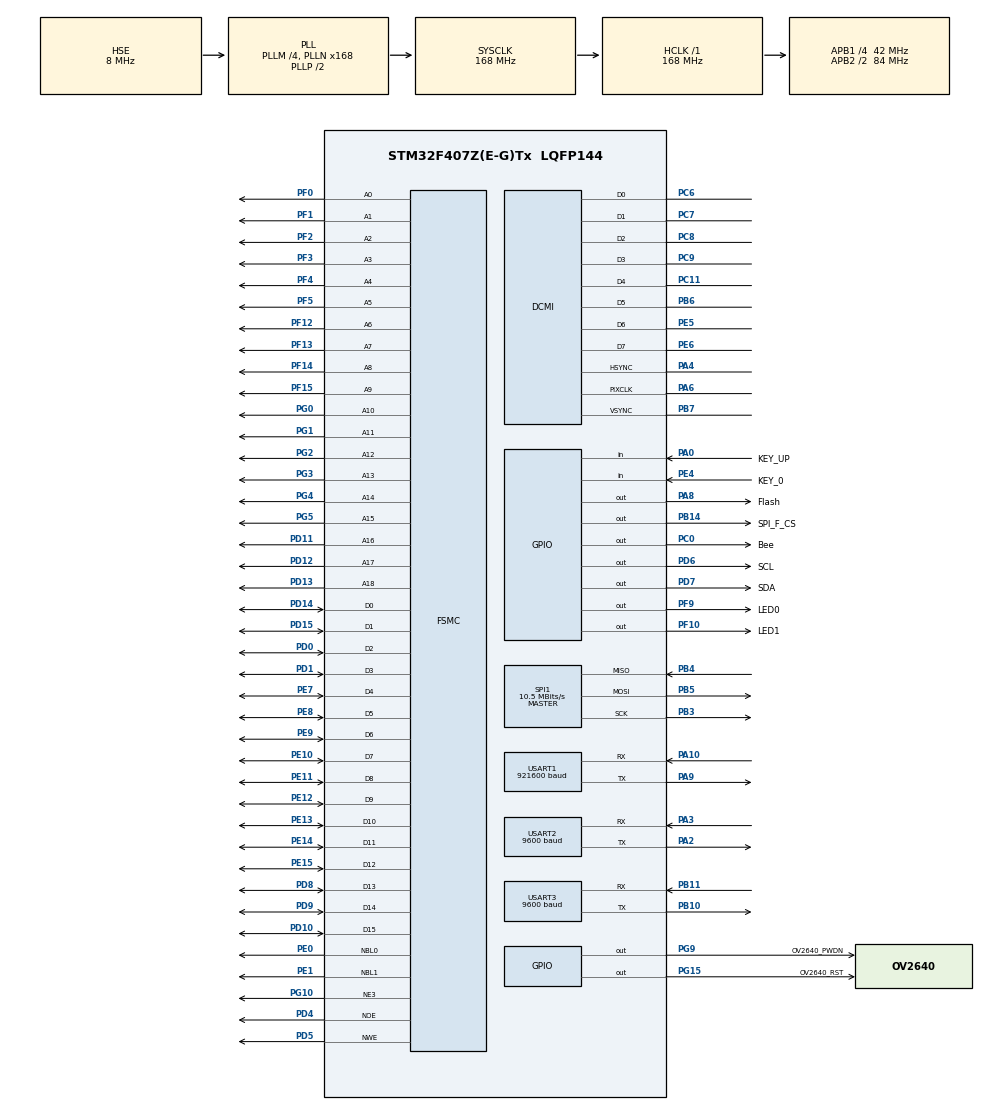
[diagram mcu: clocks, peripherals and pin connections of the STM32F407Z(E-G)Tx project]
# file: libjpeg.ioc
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DCMI.JPEGMode=DCMI_JPEG_ENABLE
DCMI.PCKPolarity=DCMI_PCKPOLARITY_RISING
Dma.DCMI.4.Direction=DMA_PERIPH_TO_MEMORY
Dma.DCMI.4.FIFOMode=DMA_FIFOMODE_DISABLE
Dma.DCMI.4.Instance=DMA2_Stream1
Dma.DCMI.4.MemDataAlignment=DMA_MDATAALIGN_WORD
Dma.DCMI.4.MemInc=DMA_MINC_ENABLE
Dma.DCMI.4.Mode=DMA_CIRCULAR
Dma.DCMI.4.PeriphDataAlignment=DMA_PDATAALIGN_WORD
Dma.DCMI.4.PeriphInc=DMA_PINC_DISABLE
Dma.DCMI.4.Priority=DMA_PRIORITY_LOW
Dma.Request0=USART1_RX
Dma.Request1=USART1_TX
Dma.Request2=USART3_RX
Dma.Request3=USART3_TX
Dma.Request4=DCMI
Dma.Request5=USART2_TX
Dma.Request6=USART2_RX
Dma.USART1_RX.0.Direction=DMA_PERIPH_TO_MEMORY
Dma.USART1_RX.0.FIFOMode=DMA_FIFOMODE_DISABLE
Dma.USART1_RX.0.Instance=DMA2_Stream2
Dma.USART1_RX.0.MemDataAlignment=DMA_MDATAALIGN_BYTE
Dma.USART1_RX.0.MemInc=DMA_MINC_ENABLE
Dma.USART1_RX.0.Mode=DMA_NORMAL
Dma.USART1_RX.0.PeriphDataAlignment=DMA_PDATAALIGN_BYTE
Dma.USART1_RX.0.PeriphInc=DMA_PINC_DISABLE
Dma.USART1_RX.0.Priority=DMA_PRIORITY_LOW
Dma.USART1_TX.1.Direction=DMA_MEMORY_TO_PERIPH
Dma.USART1_TX.1.FIFOMode=DMA_FIFOMODE_DISABLE
Dma.USART1_TX.1.Instance=DMA2_Stream7
Dma.USART1_TX.1.MemDataAlignment=DMA_MDATAALIGN_BYTE
Dma.USART1_TX.1.MemInc=DMA_MINC_ENABLE
Dma.USART1_TX.1.Mode=DMA_NORMAL
Dma.USART1_TX.1.PeriphDataAlignment=DMA_PDATAALIGN_BYTE
Dma.USART1_TX.1.PeriphInc=DMA_PINC_DISABLE
Dma.USART1_TX.1.Priority=DMA_PRIORITY_LOW
Dma.USART2_RX.6.Direction=DMA_PERIPH_TO_MEMORY
Dma.USART2_RX.6.FIFOMode=DMA_FIFOMODE_DISABLE
Dma.USART2_RX.6.Instance=DMA1_Stream5
Dma.USART2_RX.6.MemDataAlignment=DMA_MDATAALIGN_BYTE
Dma.USART2_RX.6.MemInc=DMA_MINC_ENABLE
Dma.USART2_RX.6.Mode=DMA_NORMAL
Dma.USART2_RX.6.PeriphDataAlignment=DMA_PDATAALIGN_BYTE
Dma.USART2_RX.6.PeriphInc=DMA_PINC_DISABLE
Dma.USART2_RX.6.Priority=DMA_PRIORITY_LOW
Dma.USART2_TX.5.Direction=DMA_MEMORY_TO_PERIPH
Dma.USART2_TX.5.FIFOMode=DMA_FIFOMODE_DISABLE
Dma.USART2_TX.5.Instance=DMA1_Stream6
Dma.USART2_TX.5.MemDataAlignment=DMA_MDATAALIGN_BYTE
Dma.USART2_TX.5.MemInc=DMA_MINC_ENABLE
Dma.USART2_TX.5.Mode=DMA_NORMAL
Dma.USART2_TX.5.PeriphDataAlignment=DMA_PDATAALIGN_BYTE
Dma.USART2_TX.5.PeriphInc=DMA_PINC_DISABLE
Dma.USART2_TX.5.Priority=DMA_PRIORITY_LOW
Dma.USART3_RX.2.Direction=DMA_PERIPH_TO_MEMORY
Dma.USART3_RX.2.FIFOMode=DMA_FIFOMODE_DISABLE
Dma.USART3_RX.2.Instance=DMA1_Stream1
Dma.USART3_RX.2.MemDataAlignment=DMA_MDATAALIGN_BYTE
Dma.USART3_RX.2.MemInc=DMA_MINC_ENABLE
Dma.USART3_RX.2.Mode=DMA_NORMAL
Dma.USART3_RX.2.PeriphDataAlignment=DMA_PDATAALIGN_BYTE
Dma.USART3_RX.2.PeriphInc=DMA_PINC_DISABLE
Dma.USART3_RX.2.Priority=DMA_PRIORITY_LOW
Dma.USART3_TX.3.Direction=DMA_MEMORY_TO_PERIPH
Dma.USART3_TX.3.FIFOMode=DMA_FIFOMODE_DISABLE
Dma.USART3_TX.3.Instance=DMA1_Stream3
Dma.USART3_TX.3.MemDataAlignment=DMA_MDATAALIGN_BYTE
Dma.USART3_TX.3.MemInc=DMA_MINC_ENABLE
Dma.USART3_TX.3.Mode=DMA_NORMAL
Dma.USART3_TX.3.PeriphDataAlignment=DMA_PDATAALIGN_BYTE
Dma.USART3_TX.3.PeriphInc=DMA_PINC_DISABLE
Dma.USART3_TX.3.Priority=DMA_PRIORITY_LOW
FSMC.AddressSetupTime1=0
FSMC.BusTurnAroundDuration1=0
FSMC.DataSetupTime1=9
FSMC.WriteOperation1=FSMC_WRITE_OPERATION_ENABLE
Mcu.Family=STM32F4
Mcu.Name=STM32F407Z(E-G)Tx
Mcu.Package=LQFP144
NVIC.DCMI_IRQn=true\:7\:0\:true\:false\:true\:true\:true\:true
NVIC.DMA1_Stream1_IRQn=true\:0\:0\:false\:false\:true\:false\:true\:true
NVIC.DMA1_Stream3_IRQn=true\:0\:0\:false\:false\:true\:false\:true\:true
NVIC.DMA1_Stream5_IRQn=true\:0\:0\:false\:false\:true\:false\:true\:true
NVIC.DMA1_Stream6_IRQn=true\:0\:0\:false\:false\:true\:false\:true\:true
NVIC.DMA2_Stream1_IRQn=true\:0\:0\:false\:false\:true\:false\:true\:true
NVIC.DMA2_Stream2_IRQn=true\:0\:0\:false\:false\:true\:false\:true\:true
NVIC.DMA2_Stream7_IRQn=true\:0\:0\:false\:false\:true\:false\:true\:true
NVIC.PriorityGroup=NVIC_PRIORITYGROUP_4
NVIC.TIM1_UP_TIM10_IRQn=true\:15\:0\:false\:false\:true\:true\:true\:true
NVIC.TIM6_DAC_IRQn=true\:0\:0\:false\:false\:true\:true\:true\:true
NVIC.TIM7_IRQn=true\:0\:0\:false\:false\:true\:true\:true\:true
NVIC.TimeBase=TIM1_UP_TIM10_IRQn
NVIC.TimeBaseIP=TIM1
NVIC.USART1_IRQn=true\:6\:0\:true\:false\:true\:true\:true\:true
NVIC.USART2_IRQn=true\:0\:0\:false\:false\:true\:true\:true\:true
NVIC.USART3_IRQn=true\:6\:0\:true\:false\:true\:true\:true\:true
PA0-WKUP.GPIO_Label=KEY_UP
PA0-WKUP.GPIO_PuPd=GPIO_PULLDOWN
PA0-WKUP.Signal=GPIO_Input
PA10.Mode=Asynchronous
PA10.Signal=USART1_RX
PA13.Mode=Serial_Wire
PA13.Signal=SYS_JTMS-SWDIO
PA14.Mode=Serial_Wire
PA14.Signal=SYS_JTCK-SWCLK
PA2.Mode=Asynchronous
PA2.Signal=USART2_TX
PA3.Mode=Asynchronous
PA3.Signal=USART2_RX
PA4.Mode=Slave_8_bits_External_Synchro
PA4.Signal=DCMI_HSYNC
PA6.Mode=Slave_8_bits_External_Synchro
PA6.Signal=DCMI_PIXCLK
PA8.GPIO_Label=Flash
PA8.Signal=GPIO_Output
PA9.Mode=Asynchronous
PA9.Signal=USART1_TX
PB10.Mode=Asynchronous
PB10.Signal=USART3_TX
PB11.Mode=Asynchronous
PB11.Signal=USART3_RX
PB14.GPIO_Label=SPI_F_CS
PB14.Signal=GPIO_Output
PB3.Mode=Full_Duplex_Master
PB3.Signal=SPI1_SCK
PB4.Mode=Full_Duplex_Master
PB4.Signal=SPI1_MISO
PB5.Mode=Full_Duplex_Master
PB5.Signal=SPI1_MOSI
PB6.Mode=Slave_8_bits_External_Synchro
PB6.Signal=DCMI_D5
PB7.Mode=Slave_8_bits_External_Synchro
PB7.Signal=DCMI_VSYNC
PC0.GPIO_Label=Bee
PC0.PinState=GPIO_PIN_SET
PC0.Signal=GPIO_Output
PC11.Mode=Slave_8_bits_External_Synchro
PC11.Signal=DCMI_D4
PC6.Mode=Slave_8_bits_External_Synchro
PC6.Signal=DCMI_D0
PC7.Mode=Slave_8_bits_External_Synchro
PC7.Signal=DCMI_D1
PC8.Mode=Slave_8_bits_External_Synchro
PC8.Signal=DCMI_D2
PC9.Mode=Slave_8_bits_External_Synchro
PC9.Signal=DCMI_D3
PD0.Signal=FSMC_D2_DA2
PD1.Signal=FSMC_D3_DA3
PD10.Signal=FSMC_D15_DA15
PD11.Signal=FSMC_A16_CLE
PD12.Signal=FSMC_A17_ALE
PD13.Signal=FSMC_A18
PD14.Signal=FSMC_D0_DA0
PD15.Signal=FSMC_D1_DA1
PD4.Signal=FSMC_NOE
PD5.Signal=FSMC_NWE
PD6.GPIO_Label=SCL
PD6.Signal=GPIO_Output
PD7.GPIO_Label=SDA
PD7.GPIO_ModeDefaultOutputPP=GPIO_MODE_OUTPUT_OD
PD7.GPIO_PuPd=GPIO_NOPULL
PD7.Signal=GPIO_Output
PD8.Signal=FSMC_D13_DA13
PD9.Signal=FSMC_D14_DA14
PE0.Signal=FSMC_NBL0
PE1.Signal=FSMC_NBL1
PE10.Signal=FSMC_D7_DA7
PE11.Signal=FSMC_D8_DA8
PE12.Signal=FSMC_D9_DA9
PE13.Signal=FSMC_D10_DA10
PE14.Signal=FSMC_D11_DA11
PE15.Signal=FSMC_D12_DA12
PE4.GPIO_Label=KEY_0
PE4.GPIO_PuPd=GPIO_PULLDOWN
PE4.Signal=GPIO_Input
PE5.Mode=Slave_8_bits_External_Synchro
PE5.Signal=DCMI_D6
PE6.Mode=Slave_8_bits_External_Synchro
PE6.Signal=DCMI_D7
PE7.Signal=FSMC_D4_DA4
PE8.Signal=FSMC_D5_DA5
PE9.Signal=FSMC_D6_DA6
PF0.Signal=FSMC_A0
PF1.Signal=FSMC_A1
PF10.GPIO_Label=LED1
PF10.PinState=GPIO_PIN_SET
PF10.Signal=GPIO_Output
PF12.Signal=FSMC_A6
PF13.Signal=FSMC_A7
PF14.Signal=FSMC_A8
PF15.Signal=FSMC_A9
PF2.Signal=FSMC_A2
PF3.Signal=FSMC_A3
PF4.Signal=FSMC_A4
PF5.Signal=FSMC_A5
PF9.GPIO_Label=LED0
PF9.PinState=GPIO_PIN_SET
PF9.Signal=GPIO_Output
PG0.Signal=FSMC_A10
PG1.Signal=FSMC_A11
PG10.Mode=NorPsramChipSelect3_1
PG10.Signal=FSMC_NE3
PG15.GPIO_Label=OV2640_RST
PG15.Signal=GPIO_Output
PG2.Signal=FSMC_A12
PG3.Signal=FSMC_A13
PG4.Signal=FSMC_A14
PG5.Signal=FSMC_A15
PG9.GPIO_Label=OV2640_PWDN
PG9.Signal=GPIO_Output
PH0-OSC_IN.Mode=HSE-External-Oscillator
PH0-OSC_IN.Signal=RCC_OSC_IN
PH1-OSC_OUT.Mode=HSE-External-Oscillator
PH1-OSC_OUT.Signal=RCC_OSC_OUT
ProjectManager.HeapSize=0x2000
ProjectManager.StackSize=0x2000
ProjectManager.TargetToolchain=MDK-ARM V5.32
RCC.48MHZClocksFreq_Value=84000000
RCC.AHBFreq_Value=168000000
RCC.APB1CLKDivider=RCC_HCLK_DIV4
RCC.APB1Freq_Value=42000000
RCC.APB1TimFreq_Value=84000000
RCC.APB2CLKDivider=RCC_HCLK_DIV2
RCC.APB2Freq_Value=84000000
RCC.APB2TimFreq_Value=168000000
RCC.CortexFreq_Value=168000000
RCC.HCLKFreq_Value=168000000
RCC.HSE_VALUE=8000000
RCC.HSI_VALUE=16000000
RCC.LSE_VALUE=32768
RCC.PLLM=4
RCC.PLLN=168
RCC.PLLSourceVirtual=RCC_PLLSOURCE_HSE
RCC.SYSCLKFreq_VALUE=168000000
RCC.SYSCLKSource=RCC_SYSCLKSOURCE_PLLCLK
RCC.VCOOutputFreq_Value=336000000
SH.FSMC_A0.0=FSMC_A0,19b-a1
SH.FSMC_A1.0=FSMC_A1,19b-a1
SH.FSMC_A10.0=FSMC_A10,19b-a1
SH.FSMC_A11.0=FSMC_A11,19b-a1
SH.FSMC_A12.0=FSMC_A12,19b-a1
SH.FSMC_A13.0=FSMC_A13,19b-a1
SH.FSMC_A14.0=FSMC_A14,19b-a1
SH.FSMC_A15.0=FSMC_A15,19b-a1
SH.FSMC_A16_CLE.0=FSMC_A16,19b-a1
SH.FSMC_A17_ALE.0=FSMC_A17,19b-a1
SH.FSMC_A18.0=FSMC_A18,19b-a1
SH.FSMC_A2.0=FSMC_A2,19b-a1
SH.FSMC_A3.0=FSMC_A3,19b-a1
SH.FSMC_A4.0=FSMC_A4,19b-a1
SH.FSMC_A5.0=FSMC_A5,19b-a1
SH.FSMC_A6.0=FSMC_A6,19b-a1
SH.FSMC_A7.0=FSMC_A7,19b-a1
SH.FSMC_A8.0=FSMC_A8,19b-a1
SH.FSMC_A9.0=FSMC_A9,19b-a1
SH.FSMC_D0_DA0.0=FSMC_D0,16b-d1
SH.FSMC_D10_DA10.0=FSMC_D10,16b-d1
SH.FSMC_D11_DA11.0=FSMC_D11,16b-d1
SH.FSMC_D12_DA12.0=FSMC_D12,16b-d1
SH.FSMC_D13_DA13.0=FSMC_D13,16b-d1
SH.FSMC_D14_DA14.0=FSMC_D14,16b-d1
SH.FSMC_D15_DA15.0=FSMC_D15,16b-d1
SH.FSMC_D1_DA1.0=FSMC_D1,16b-d1
SH.FSMC_D2_DA2.0=FSMC_D2,16b-d1
SH.FSMC_D3_DA3.0=FSMC_D3,16b-d1
SH.FSMC_D4_DA4.0=FSMC_D4,16b-d1
SH.FSMC_D5_DA5.0=FSMC_D5,16b-d1
SH.FSMC_D6_DA6.0=FSMC_D6,16b-d1
SH.FSMC_D7_DA7.0=FSMC_D7,16b-d1
SH.FSMC_D8_DA8.0=FSMC_D8,16b-d1
SH.FSMC_D9_DA9.0=FSMC_D9,16b-d1
SH.FSMC_NBL0.0=FSMC_NBL0,2ByteEnable1
SH.FSMC_NBL1.0=FSMC_NBL1,2ByteEnable1
SH.FSMC_NOE.0=FSMC_NOE,Sram1
SH.FSMC_NWE.0=FSMC_NWE,Sram1
SPI1.BaudRatePrescaler=SPI_BAUDRATEPRESCALER_8
SPI1.CLKPhase=SPI_PHASE_2EDGE
SPI1.CLKPolarity=SPI_POLARITY_HIGH
SPI1.CalculateBaudRate=10.5 MBits/s
SPI1.Direction=SPI_DIRECTION_2LINES
SPI1.Mode=SPI_MODE_MASTER
SPI1.VirtualType=VM_MASTER
STMicroelectronics.X-CUBE-AI.9.1.0.ActivationBufferSizeList=74152
STMicroelectronics.X-CUBE-AI.9.1.0.ActivationBuffers=pool0
STMicroelectronics.X-CUBE-AI.9.1.0.ActivationNames=pool0
STMicroelectronics.X-CUBE-AI.9.1.0.ActivationSizes=AI_NETWORK_DATA_ACTIVATION_1_SIZE
STMicroelectronics.X-CUBE-AI.9.1.0.HeapSize=0x2000
STMicroelectronics.X-CUBE-AI.9.1.0.InternalRamActivationBufferMaxSize=AI_NETWORK_DATA_ACTIVATIONS_SIZE
STMicroelectronics.X-CUBE-AI.9.1.0.LatestDirectoryUsed-3eacd147dd0d0e82aa5a491c572b6a6953748387bc85e0ce3336f93af9375877=C\:\\Users\\18033\\Desktop
STMicroelectronics.X-CUBE-AI.9.1.0.MaximumNumberOfInputLayer=1
STMicroelectronics.X-CUBE-AI.9.1.0.MaximumNumberOfOutputLayer=1
STMicroelectronics.X-CUBE-AI.9.1.0.MaximumSizeOfInputLayer=1
STMicroelectronics.X-CUBE-AI.9.1.0.MaximumSizeOfOutputLayer=1
STMicroelectronics.X-CUBE-AI.9.1.0.ModelActualCompression-3eacd147dd0d0e82aa5a491c572b6a6953748387bc85e0ce3336f93af9375877=0.0
STMicroelectronics.X-CUBE-AI.9.1.0.ModelCompression-3eacd147dd0d0e82aa5a491c572b6a6953748387bc85e0ce3336f93af9375877=None
STMicroelectronics.X-CUBE-AI.9.1.0.ModelFlashOccupation-3eacd147dd0d0e82aa5a491c572b6a6953748387bc85e0ce3336f93af9375877=397240
STMicroelectronics.X-CUBE-AI.9.1.0.ModelHashList=3eacd147dd0d0e82aa5a491c572b6a6953748387bc85e0ce3336f93af9375877
STMicroelectronics.X-CUBE-AI.9.1.0.ModelKind-3eacd147dd0d0e82aa5a491c572b6a6953748387bc85e0ce3336f93af9375877=TFLITE
STMicroelectronics.X-CUBE-AI.9.1.0.ModelMacc-3eacd147dd0d0e82aa5a491c572b6a6953748387bc85e0ce3336f93af9375877=7277168
STMicroelectronics.X-CUBE-AI.9.1.0.ModelName-3eacd147dd0d0e82aa5a491c572b6a6953748387bc85e0ce3336f93af9375877=network
STMicroelectronics.X-CUBE-AI.9.1.0.ModelNameList=network
STMicroelectronics.X-CUBE-AI.9.1.0.ModelRamOccupation-3eacd147dd0d0e82aa5a491c572b6a6953748387bc85e0ce3336f93af9375877=74152
STMicroelectronics.X-CUBE-AI.9.1.0.ModelStructureFile-3eacd147dd0d0e82aa5a491c572b6a6953748387bc85e0ce3336f93af9375877=C\:\\Users\\18033\\Desktop\\hrnetlite18_lite_40_new_rgb.tflite
STMicroelectronics.X-CUBE-AI.9.1.0.ModelType-3eacd147dd0d0e82aa5a491c572b6a6953748387bc85e0ce3336f93af9375877=STM32Cube.AI MCU runtime
STMicroelectronics.X-CUBE-AI.9.1.0.ReadyForCodeGeneration=true
STMicroelectronics.X-CUBE-AI.9.1.0.StackSize=0x2000
STMicroelectronics.X-CUBE-AI.9.1.0.WorkingBufferStartAddrList=0xFFFFFFFF
STMicroelectronics.X-CUBE-AI.9.1.0.XAaCUBEAaAICcArtificialOoIntelligenceJjCore=true
STMicroelectronics.X-CUBE-AI.9.1.0.copyWeightToRam-3eacd147dd0d0e82aa5a491c572b6a6953748387bc85e0ce3336f93af9375877=false
STMicroelectronics.X-CUBE-AI.9.1.0.customLayerConfigEnabled-3eacd147dd0d0e82aa5a491c572b6a6953748387bc85e0ce3336f93af9375877=false
STMicroelectronics.X-CUBE-AI.9.1.0.extFlashSize-3eacd147dd0d0e82aa5a491c572b6a6953748387bc85e0ce3336f93af9375877=16
STMicroelectronics.X-CUBE-AI.9.1.0.noOnnxIoTranspose-3eacd147dd0d0e82aa5a491c572b6a6953748387bc85e0ce3336f93af9375877=false
STMicroelectronics.X-CUBE-AI.9.1.0.useInputAllocation-3eacd147dd0d0e82aa5a491c572b6a6953748387bc85e0ce3336f93af9375877=true
STMicroelectronics.X-CUBE-AI.9.1.0.useOutputAllocation-3eacd147dd0d0e82aa5a491c572b6a6953748387bc85e0ce3336f93af9375877=true
TIM10.Period=999
TIM10.Prescaler=83
TIM6.Prescaler=83
TIM7.Period=9999
TIM7.Prescaler=8399
USART1.BaudRate=921600
USART1.VirtualMode=VM_ASYNC
USART2.BaudRate=9600
USART2.VirtualMode=VM_ASYNC
USART3.BaudRate=9600
USART3.VirtualMode=VM_ASYNC
VP_STMicroelectronics.X-CUBE-AI_VS_ArtificialOoIntelligenceJjXAaCUBEAaAI_9.1.0.Mode=ArtificialOoIntelligenceJjXAaCUBEAaAI
VP_SYS_VS_tim1.Mode=TIM1
VP_TIM10_VS_ClockSourceINT.Mode=Enable_Timer
VP_TIM6_VS_ClockSourceINT.Mode=Enable_Timer
VP_TIM7_VS_ClockSourceINT.Mode=Enable_Timer
board=custom

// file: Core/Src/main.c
/* USER CODE BEGIN Header */
/**
  ******************************************************************************
  * @file           : main.c
  * @brief          : Main program body
  ******************************************************************************
  * @attention
  *
  * Copyright (c) 2023 STMicroelectronics.
  * All rights reserved.
  *
  * This software is licensed under terms that can be found in the LICENSE file
  * in the root directory of this software component.
  * If no LICENSE file comes with this software, it is provided AS-IS.
  *
  ******************************************************************************
  */
/* USER CODE END Header */
#include "main.h"
#include "dcmi.h"
#include "dma.h"
#include "spi.h"
#include "tim.h"
#include "usart.h"
#include "gpio.h"
#include "fsmc.h"

/* USER CODE BEGIN Includes */
#include "stdio.h"
#include "string.h"
#include "ov2640.h"
#include "math.h"
#include "jpeg.h"
#include "stm32f4xx_it.h"
#include <setjmp.h>
#include "network.h"
#include "network_data.h"
#include "w25flash.h"
/* USER CODE END Includes */

/* USER CODE BEGIN PTD */

//uint32_t a_DcmiDmaRxBuff[DEF_DcmiDmaRxBuff_Size] __attribute__((at(0x684FC000)));
extern uint8_t rgb888[3][Width_raw*Height_raw] __attribute__((at(0x68531800)));
extern uint8_t ov2640_mode;
/* USER CODE END PTD */

/* USER CODE BEGIN PM */

uint8_t trans_uart2[100];
uint8_t trans_uart3[100];
int cnt[100];
uint8_t frame = 0;
uint8_t RxBuf[4]; // ���ջ���??
uint8_t dataReceived = 0; // �洢���յ�������
uint8_t variable = 0; // ����
//char buffer[10][100];

/* Global handle to reference the instantiated C-model */
ai_handle network = AI_HANDLE_NULL;

/* Global c-array to handle the activations buffer */
AI_ALIGNED(32)
ai_u8 activations[AI_NETWORK_DATA_ACTIVATIONS_SIZE];

/* Array to store the data of the input tensor */
AI_ALIGNED(32)
ai_float in_data[AI_NETWORK_IN_1_SIZE] ;

	//static uint16_t in_data[2700];
/* or static ai_float in_data[AI_NETWORK_IN_1_SIZE_BYTES]; */

/* c-array to store the data of the output tensor */
AI_ALIGNED(32)
ai_float out_data[AI_NETWORK_OUT_1_SIZE];
/* static ai_u8 out_data[AI_NETWORK_OUT_1_SIZE_BYTES]; */

/* Array of pointer to manage the model's input/output tensors */
ai_buffer *ai_input;
ai_buffer *ai_output;

/* USER CODE END PM */

/* USER CODE BEGIN PV */
void ImgShow(uint8_t flag)
{
	if(flag==0){
			memset(trans_uart3,0,sizeof(trans_uart3));
			int len=sprintf((char *)trans_uart3,"p0.pic=0\xff\xff\xff");
			HAL_UART_Transmit_IT(&huart3,trans_uart3,len);
	}else if(flag==1){
			memset(trans_uart3,0,sizeof(trans_uart3));
			int len=sprintf((char *)trans_uart3,"p0.pic=1\xff\xff\xff");
			HAL_UART_Transmit_IT(&huart3,trans_uart3,len);
	}else if(flag==2){
			memset(trans_uart3,0,sizeof(trans_uart3));
			int len=sprintf((char *)trans_uart3,"p0.pic=2\xff\xff\xff");
			HAL_UART_Transmit_IT(&huart3,trans_uart3,len);
	}else if(flag==3){
			memset(trans_uart3,0,sizeof(trans_uart3));
			int len=sprintf((char *)trans_uart3,"p0.pic=3\xff\xff\xff");
			HAL_UART_Transmit_IT(&huart3,trans_uart3,len);
	}
}
int aiInit(void) {
  ai_error err;

  /* Create and initialize the c-model */
  const ai_handle acts[] = { activations };
  err = ai_network_create_and_init(&network, acts, NULL);
  if (err.type != AI_ERROR_NONE) { return -1;};

  /* Reteive pointers to the model's input/output tensors */
  ai_input = ai_network_inputs_get(network, NULL);
  ai_output = ai_network_outputs_get(network, NULL);

  return 0;
}

/*
 * Run inference
 */
int aiRun(const void *in_data, void *out_data) {
  ai_i32 n_batch;

  /* 1 - Update IO handlers with the data payload *//* 1 -?????????IO????*/
  ai_input[0].data = AI_HANDLE_PTR(in_data);
  ai_output[0].data = AI_HANDLE_PTR(out_data);

  /* 2 - Perform the inference *//* 2 -????*/
  n_batch = ai_network_run(network, &ai_input[0], &ai_output[0]);
  if (n_batch != 1) {
      ai_network_get_error(network);
  };

  return 0;
}

void initialize_rgb888() {
    for (int i = 0; i < 3; i++) {
        for (int j = 0; j < Width_raw * Height_raw; j++) {
            rgb888[i][j] = 0;
        }
    }
}
/* USER CODE END PV */

void SystemClock_Config(void);

int main(void)
{

  /* MCU Configuration--------------------------------------------------------*/

  /* Reset of all peripherals, Initializes the Flash interface and the Systick. */
  HAL_Init();

  /* Configure the system clock */
  SystemClock_Config();

  /* Initialize all configured peripherals */
  MX_GPIO_Init();
  MX_DMA_Init();
  MX_USART1_UART_Init();
  MX_USART3_UART_Init();
  MX_DCMI_Init();
  MX_FSMC_Init();
  MX_SPI1_Init();
  MX_TIM6_Init();
  MX_TIM7_Init();
  MX_TIM10_Init();
  MX_USART2_UART_Init();
  /* USER CODE BEGIN 2 */
	while(norflash_init());
	initialize_rgb888();
  HAL_TIM_Base_Start_IT(&htim7);
	HAL_TIM_Base_Start_IT(&htim10);
  DCMI->IER = 0x0;
  __HAL_DCMI_ENABLE(&hdcmi);
  __HAL_DCMI_ENABLE_IT(&hdcmi,DCMI_IT_FRAME);
	rgb_init();
  HAL_UART_Receive_IT(&huart2, RxBuf, 1);
  aiInit();
	ImgShow(3);
//	for(int i=0;i < 4096;i++)
//	{
//		in_data[i]=1;
//	}
//	aiRun(in_data,out_data);
  /* USER CODE END 2 */

  /* Infinite loop */
  /* USER CODE BEGIN WHILE */
  while (1)
  {
		if((double)out_data[2]<0.1&&out_data[2]!=0&&dataReceived)
		{
					if((double)(out_data[1]-out_data[0])>0)
						HAL_GPIO_WritePin(Bee_GPIO_Port, Bee_Pin, (GPIO_PinState)0);
					else
						HAL_GPIO_WritePin(Bee_GPIO_Port, Bee_Pin, (GPIO_PinState)1);
		}
		else
		{
				HAL_GPIO_WritePin(Bee_GPIO_Port, Bee_Pin, (GPIO_PinState)1);
		}
		if(out_data[0]!=0){
			if((double)out_data[2]<0.1&&out_data[2]!=0)
			{
						if((double)(out_data[1]-out_data[0])>0)
							ImgShow(2);
						else
							ImgShow(1);
			}
			else
			{
					ImgShow(0);
			}
		}else{
				ImgShow(3);
		}
		rgb_test();

		aiRun(in_data,out_data);
//		fsmc_sram_test();
    /* USER CODE END WHILE */

  }
}

void SystemClock_Config(void)
{
  RCC_OscInitTypeDef RCC_OscInitStruct = {0};
  RCC_ClkInitTypeDef RCC_ClkInitStruct = {0};

  /** Configure the main internal regulator output voltage
  */
  __HAL_RCC_PWR_CLK_ENABLE();
  __HAL_PWR_VOLTAGESCALING_CONFIG(PWR_REGULATOR_VOLTAGE_SCALE1);

  /** Initializes the RCC Oscillators according to the specified parameters
  * in the RCC_OscInitTypeDef structure.
  */
  RCC_OscInitStruct.OscillatorType = RCC_OSCILLATORTYPE_HSE;
  RCC_OscInitStruct.HSEState = RCC_HSE_ON;
  RCC_OscInitStruct.PLL.PLLState = RCC_PLL_ON;
  RCC_OscInitStruct.PLL.PLLSource = RCC_PLLSOURCE_HSE;
  RCC_OscInitStruct.PLL.PLLM = 4;
  RCC_OscInitStruct.PLL.PLLN = 168;
  RCC_OscInitStruct.PLL.PLLP = RCC_PLLP_DIV2;
  RCC_OscInitStruct.PLL.PLLQ = 4;
  if (HAL_RCC_OscConfig(&RCC_OscInitStruct) != HAL_OK)
  {
    Error_Handler();
  }

  /** Initializes the CPU, AHB and APB buses clocks
  */
  RCC_ClkInitStruct.ClockType = RCC_CLOCKTYPE_HCLK|RCC_CLOCKTYPE_SYSCLK
                              |RCC_CLOCKTYPE_PCLK1|RCC_CLOCKTYPE_PCLK2;
  RCC_ClkInitStruct.SYSCLKSource = RCC_SYSCLKSOURCE_PLLCLK;
  RCC_ClkInitStruct.AHBCLKDivider = RCC_SYSCLK_DIV1;
  RCC_ClkInitStruct.APB1CLKDivider = RCC_HCLK_DIV4;
  RCC_ClkInitStruct.APB2CLKDivider = RCC_HCLK_DIV2;

  if (HAL_RCC_ClockConfig(&RCC_ClkInitStruct, FLASH_LATENCY_5) != HAL_OK)
  {
    Error_Handler();
  }
}

/* USER CODE BEGIN 4 */

void HAL_DCMI_FrameEventCallback(DCMI_HandleTypeDef *hdcmi)
{
	frame=1;
	if(ov2640_mode){
    __HAL_DCMI_CLEAR_FLAG(hdcmi, DCMI_FLAG_FRAMERI);    /* ���֡�ж�????? */
	    __HAL_DCMI_ENABLE_IT(hdcmi, DCMI_IT_FRAME);
	    jpeg_data_process();    /* jpeg���ݴ��� */
	}

//	     uint8_t *p = (uint8_t *)SRAM_ADDR;

//        for (int i = 0; i < DEF_DcmiDmaRxBuff_Size*4; i++) {
////					printf("[%d]",i);
//					printf(",%d",(uint8_t)*p);
//					p++;
//           while ((USART1->SR & 0X40) == 0);

//       }

	HAL_GPIO_TogglePin(LED0_GPIO_Port,LED0_Pin);

    /* ����ʹ��֡�ж�,��ΪHAL_DCMI_IRQHandler()������ر�֡�ж�????? */

}
void HAL_UART_RxCpltCallback(UART_HandleTypeDef *huart)
{
    static uint8_t index = 0;
    static uint8_t buffer[4];

    if (huart->Instance == USART2)
    {
				if(index == 0 && RxBuf[0]!=0xA5){
					HAL_UART_Receive_IT(&huart2, RxBuf, 1);
					return;
				}
        buffer[index++] = RxBuf[0];

        if (index == 4)
        {
            index = 0;
            if (buffer[0] == 0xA5 && buffer[3] == 0x5A) // �?查头和尾
            {
                uint8_t checksum = buffer[1];
                if ((checksum & 0xFF) == buffer[2]) // �?查校验码
                {
                    dataReceived = buffer[1];

                }
            }
        }

        // 继续接收下一个字�?
        HAL_UART_Receive_IT(&huart2, RxBuf, 1);
    }
}
/* USER CODE END 4 */

void HAL_TIM_PeriodElapsedCallback(TIM_HandleTypeDef *htim)
{
  /* USER CODE BEGIN Callback 0 */
  if (htim == &htim10)
  {

		cnt[0]++;
		if(cnt[0]==1000)
		{
			memset(trans_uart2,0,sizeof(trans_uart2));
			int len=sprintf((char *)trans_uart2,"[0]%f,[1]%f,[2]%f\r\n",out_data[0],out_data[1],out_data[2]);
			HAL_UART_Transmit_IT(&huart2,trans_uart2,len);
//			frame=0;
			cnt[0]=0;
			HAL_GPIO_TogglePin(LED1_GPIO_Port, LED1_Pin);
//			OV2640_FLASH(1);
//    ov2640_write_reg(0xFF, 0x01);
//    ov2640_write_reg(0x4B, 0x81);
//    ov2640_write_reg(0x4B, 0x01);
		}

  }

  /* USER CODE END Callback 0 */
  if (htim->Instance == TIM1)
  {
    HAL_IncTick();
  }
}

void Error_Handler(void)
{
  __disable_irq();
  while (1)
  {
  }
}
